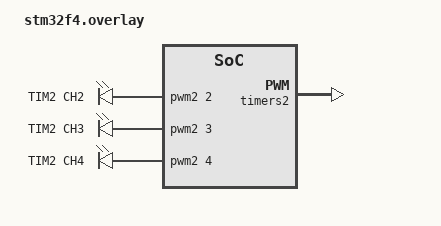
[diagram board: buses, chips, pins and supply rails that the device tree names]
&timers2 {
    status = "okay";

    pwm2: pwm {
        status = "okay";
        pinctrl-0 = <&tim2_ch2_pa1 &tim2_ch3_pa2 &tim2_ch4_pa3>;
        pinctrl-names = "default";
    };
};

/ {
    aliases {
        pwma1 = &pwm_led_0;
        pwma2 = &pwm_led_1;
        pwma3 = &pwm_led_2;
    };

    pwms {
        compatible = "pwm-leds";

        pwm_led_0: pwm_led_0 {
            pwms = <&pwm2 2 PWM_MSEC(20) PWM_POLARITY_INVERTED>;
            label = "TIM2 CH2";
        };
        pwm_led_1: pwm_led_1 {
            pwms = <&pwm2 3 PWM_MSEC(20) PWM_POLARITY_INVERTED>;
            label = "TIM2 CH3";
        };
        pwm_led_2: pwm_led_2 {
            pwms = <&pwm2 4 PWM_MSEC(20) PWM_POLARITY_INVERTED>;
            label = "TIM2 CH4";
        };
    };
};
